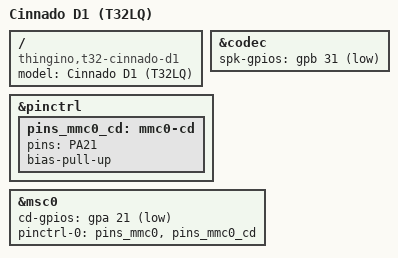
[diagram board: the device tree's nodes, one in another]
// SPDX-License-Identifier: GPL-2.0
#include "thingino-t32.dts"
#include <dt-bindings/gpio/gpio.h>

/ {
	compatible = "thingino,t32-cinnado-d1", "thingino,t32", "ingenic,t32";
	model = "Cinnado D1 (T32LQ)";
};

/* Speaker amplifier enable: PB31, low enables it */
&codec {
	spk-gpios = <&gpb 31 GPIO_ACTIVE_LOW>;
};

/* The card slot's detect switch is on PA21, closed to ground by a card */
&pinctrl {
	pins_mmc0_cd: mmc0-cd {
		pins = "PA21";
		bias-pull-up;
	};
};

&msc0 {
	/delete-property/ broken-cd;
	cd-gpios = <&gpa 21 GPIO_ACTIVE_LOW>;

	pinctrl-0 = <&pins_mmc0>, <&pins_mmc0_cd>;
};
